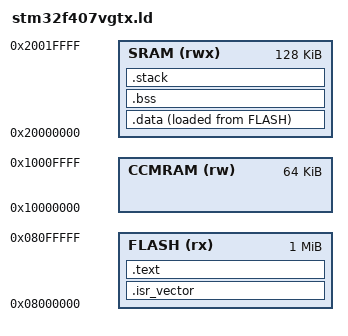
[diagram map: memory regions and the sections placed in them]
/* STM32F407VGT6: 1MB Flash, 192KB SRAM */

ENTRY(Reset_Handler)

MEMORY
{
    FLASH (rx)  : ORIGIN = 0x08000000, LENGTH = 1024K
    SRAM  (rwx) : ORIGIN = 0x20000000, LENGTH = 128K
    CCMRAM (rw) : ORIGIN = 0x10000000, LENGTH = 64K
}

SECTIONS
{
    .isr_vector :
    {
        KEEP(*(.isr_vector))
    } > FLASH

    .text :
    {
        *(.text)
        *(.text*)
        *(.rodata)
        *(.rodata*)
        _etext = .;
    } > FLASH

    _sidata = LOADADDR(.data);

    .data :
    {
        _sdata = .;
        *(.data)
        *(.data*)
        _edata = .;
    } > SRAM AT> FLASH

    .bss :
    {
        _sbss = .;
        __bss_start__ = _sbss;
        *(.bss)
        *(.bss*)
        *(COMMON)
        _ebss = .;
        __bss_end__ = _ebss;
    } > SRAM

    .stack (NOLOAD) :
    {
        . = ALIGN(8);
        _end = .;
        PROVIDE(end = .);
    } > SRAM
}
